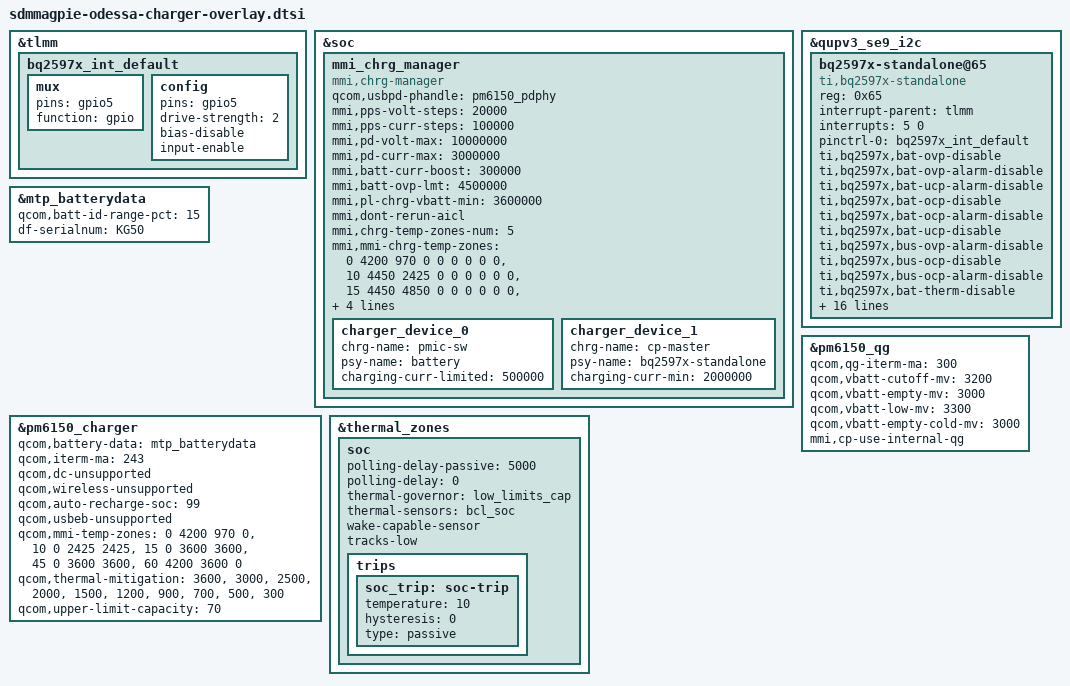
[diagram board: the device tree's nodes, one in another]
#include <dt-bindings/gpio/gpio.h>
#include <dt-bindings/pinctrl/qcom,pmic-gpio.h>

&tlmm{
	bq2597x_int_default: bq2597x_int_default {
		mux {
			pins = "gpio5";
			function = "gpio";
		};

		config {
			pins = "gpio5";
			drive-strength = <2>; /* 2 MA */
			bias-disable;
			input-enable;
		};
	};
};

&soc {
	mmi_chrg_manager {
		compatible = "mmi,chrg-manager";
		qcom,usbpd-phandle = <&pm6150_pdphy>;
		mmi,pps-volt-steps = <20000>;
		mmi,pps-curr-steps = <100000>;
		mmi,pd-volt-max = <10000000>;
		mmi,pd-curr-max = <3000000>;
		mmi,batt-curr-boost = <300000>;
		mmi,batt-ovp-lmt = <4500000>;
		mmi,pl-chrg-vbatt-min = <3600000>;
		mmi,dont-rerun-aicl;
		mmi,chrg-temp-zones-num = <5>;
		mmi,mmi-chrg-temp-zones =
					<0 4200 970 0 0 0 0 0 0>,
					<10 4450 2425 0 0 0 0 0 0>,
					<15 4450 4850 0 0 0 0 0 0>,
					<45 4350 6000 4450 4000 0 0 0 0>,
					<60 4200 4850 0 0 0 0 0 0>;
		mmi,thermal-mitigation =
					<6000000>,
					<5000000>,
					<4000000>,
					<3000000>,
					<2000000>;
		charger_device_0 {
			chrg-name = "pmic-sw";
			psy-name = "battery";
			charging-curr-limited = <500000>;
		};
		charger_device_1 {
			chrg-name = "cp-master";
			psy-name = "bq2597x-standalone";
			charging-curr-min = <2000000>;
		};
	};
};

&qupv3_se9_i2c {
	status = "okay";

	bq2597x-standalone@65 {
		compatible = "ti,bq2597x-standalone";
		reg = <0x65>;

		/delete-property/ interrupts;
		interrupt-parent = <&tlmm>;
		interrupts = <5 0>;
		interrupt-names = "bq2597x_irq";
		pinctrl-names = "default";
		pinctrl-0 = <&bq2597x_int_default>;
		ti,bq2597x,bat-ovp-disable;
		ti,bq2597x,bat-ovp-alarm-disable;
		ti,bq2597x,bat-ucp-alarm-disable;
		ti,bq2597x,bat-ocp-disable;
		ti,bq2597x,bat-ocp-alarm-disable;

		ti,bq2597x,bat-ucp-disable;

		ti,bq2597x,bus-ovp-alarm-disable;
		ti,bq2597x,bus-ocp-disable;
		ti,bq2597x,bus-ocp-alarm-disable;


		ti,bq2597x,bat-therm-disable;
		ti,bq2597x,bus-therm-disable;
		ti,bq2597x,die-therm-disable;

		ti,bq2597x,bat-ovp-threshold = <4525>;
		ti,bq2597x,bat-ovp-alarm-threshold = <4400>;
		ti,bq2597x,bat-ocp-threshold = <8000>;
		ti,bq2597x,bat-ocp-alarm-threshold = <6500>;

		ti,bq2597x,bus-ovp-threshold = <12000>;
		ti,bq2597x,bus-ovp-alarm-threshold = <11000>;
		ti,bq2597x,bus-ocp-threshold = <3750>;
		ti,bq2597x,bus-ocp-alarm-threshold = <3500>;

		ti,bq2597x,bat-ucp-alarm-threshold = <2000>;

		ti,bq2597x,bat-therm-threshold = <0x15>;/*4.1%*/
		ti,bq2597x,bus-therm-threshold = <0x15>;/*4.1%*/
		ti,bq2597x,die-therm-threshold = <125>;

		ti,bq2597x,ac-ovp-threshold = <17>;
		ti,bq2597x,sense-resistor-mohm = <5>;

	};
};

&mtp_batterydata {
       qcom,batt-id-range-pct = <15>;
       df-serialnum = "KG50";
       #include "qg-batterydata-kg50-4000mah.dtsi"
};

&pm6150_charger {
	/delete-property/qcom,support-mods;
	qcom,battery-data = <&mtp_batterydata>;
	qcom,iterm-ma = <243>;
	qcom,dc-unsupported;
	qcom,wireless-unsupported;
	qcom,auto-recharge-soc = <99>;
	qcom,usbeb-unsupported;
	qcom,mmi-temp-zones = <0 4200 970 0>,
				<10 0 2425 2425>,
				<15 0 3600 3600>,
				<45 0 3600 3600>,
				<60 4200 3600 0>;
	qcom,thermal-mitigation = <3600>,
				   <3000>,
				   <2500>,
				   <2000>,
				   <1500>,
				   <1200>,
				   <900>,
				   <700>,
				   <500>,
				   <300>;
	qcom,upper-limit-capacity = <70>;
};

&pm6150_qg {
	qcom,qg-iterm-ma = <300>;
	qcom,vbatt-cutoff-mv = <3200>;
	qcom,vbatt-empty-mv = <3000>;
	qcom,vbatt-low-mv = <3300>;
	qcom,vbatt-empty-cold-mv = <3000>;
	mmi,cp-use-internal-qg;
};

&thermal_zones {
	soc {
		polling-delay-passive = <5000>;
		polling-delay = <0>;
		thermal-governor = "low_limits_cap";
		thermal-sensors = <&bcl_soc>;
		wake-capable-sensor;
		tracks-low;

		trips {
			soc_trip:soc-trip {
				temperature = <10>;
				hysteresis = <0>;
				type = "passive";
			};
		};
	};
};
